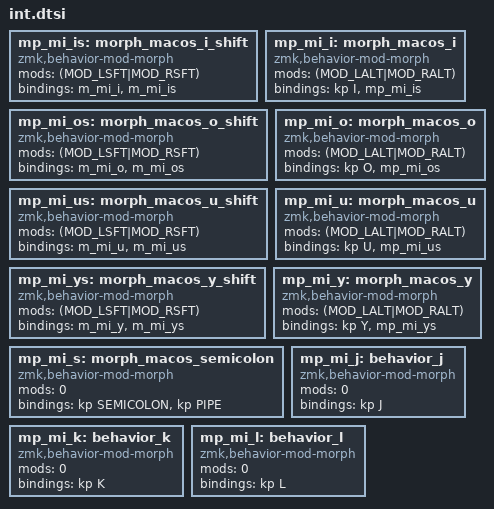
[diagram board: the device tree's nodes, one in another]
// tap:         i
// alt:         í
// alt+shift:   Í
mp_mi_is: morph_macos_i_shift {
    compatible = "zmk,behavior-mod-morph";
    #binding-cells = <0>;
    mods = <(MOD_LSFT|MOD_RSFT)>;
    bindings = <&m_mi_i>, <&m_mi_is>;
};
mp_mi_i: morph_macos_i {
    compatible = "zmk,behavior-mod-morph";
    #binding-cells = <0>;
    mods = <(MOD_LALT|MOD_RALT)>;
    bindings = <&kp I>, <&mp_mi_is>;
};

// tap:         o
// alt:         ó
// alt+shift:   Ó
mp_mi_os: morph_macos_o_shift {
    compatible = "zmk,behavior-mod-morph";
    #binding-cells = <0>;
    mods = <(MOD_LSFT|MOD_RSFT)>;
    bindings = <&m_mi_o>, <&m_mi_os>;
};
mp_mi_o: morph_macos_o {
    compatible = "zmk,behavior-mod-morph";
    #binding-cells = <0>;
    mods = <(MOD_LALT|MOD_RALT)>;
    bindings = <&kp O>, <&mp_mi_os>;
};

// tap:         u
// alt:         ú
// alt+shift:   Ú
mp_mi_us: morph_macos_u_shift {
    compatible = "zmk,behavior-mod-morph";
    #binding-cells = <0>;
    mods = <(MOD_LSFT|MOD_RSFT)>;
    bindings = <&m_mi_u>, <&m_mi_us>;
};
mp_mi_u: morph_macos_u {
    compatible = "zmk,behavior-mod-morph";
    #binding-cells = <0>;
    mods = <(MOD_LALT|MOD_RALT)>;
    bindings = <&kp U>, <&mp_mi_us>;
};

// tap:         y
// alt:         ü
// alt+shift:   Ü
mp_mi_ys: morph_macos_y_shift {
    compatible = "zmk,behavior-mod-morph";
    #binding-cells = <0>;
    mods = <(MOD_LSFT|MOD_RSFT)>;
    bindings = <&m_mi_y>, <&m_mi_ys>;
};
mp_mi_y: morph_macos_y {
    compatible = "zmk,behavior-mod-morph";
    #binding-cells = <0>;
    mods = <(MOD_LALT|MOD_RALT)>;
    bindings = <&kp Y>, <&mp_mi_ys>;
};

mp_mi_s: morph_macos_semicolon {
    compatible = "zmk,behavior-mod-morph";
    #binding-cells = <0>;
    mods = <0>;  // Добавляем обязательный параметр
    bindings = <&kp SEMICOLON>, <&kp PIPE>;  // Alt → |
};
mp_mi_j: behavior_j {
    compatible = "zmk,behavior-mod-morph";
    #binding-cells = <0>;
    mods = <0>;  // Добавляем обязательный параметр
    bindings = <&kp J>;
};

mp_mi_k: behavior_k {
    compatible = "zmk,behavior-mod-morph";
    #binding-cells = <0>;
    mods = <0>;
    bindings = <&kp K>;
};

mp_mi_l: behavior_l {
    compatible = "zmk,behavior-mod-morph";
    #binding-cells = <0>;
    mods = <0>;
    bindings = <&kp L>;
};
